AUTOSAR XML (schema 4-2-2)
package /ASW_NM
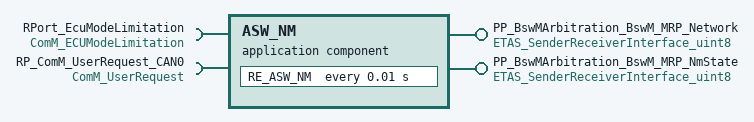
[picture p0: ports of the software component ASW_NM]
  application sw component type ASW_NM
    require port RPort_EcuModeLimitation: required-interface=ComM_ECUModeLimitation
    require port RP_ComM_UserRequest_CAN0: required-interface=ComM_UserRequest
    provide port PP_BswMArbitration_BswM_MRP_Network: provided-interface=ETAS_SenderReceiverInterface_uint8
    provide port PP_BswMArbitration_BswM_MRP_NmState: provided-interface=ETAS_SenderReceiverInterface_uint8
    behavior IB_ASW_NM: data-type-mapping=ComMModeMapping
      timing event TE_ASW_Nm_10ms: start-on-event=RE_ASW_NM, period=0.01
      runnable RE_ASW_NM: symbol=RE_ASW_NM_func
        data-send-points:
          access DSP_uint8_0: accessed-variable=PP_BswMArbitration_BswM_MRP_Network.uint8
          access DSP_uint8_1: accessed-variable=PP_BswMArbitration_BswM_MRP_NmState.uint8
        8 x sync call:
          SynchronousServerCallPoint_0: operation=RPort_EcuModeLimitation.LimitECUToNoComMode
          SynchronousServerCallPoint_1: operation=RPort_EcuModeLimitation.ReadInhibitCounter
          SynchronousServerCallPoint_2: operation=RPort_EcuModeLimitation.ResetInhibitCounter
          SynchronousServerCallPoint_3: operation=RPort_EcuModeLimitation.SetECUGroupClassification
          SynchronousServerCallPoint_4: operation=RP_ComM_UserRequest_CAN0.GetCurrentComMode
          SynchronousServerCallPoint_5: operation=RP_ComM_UserRequest_CAN0.GetMaxComMode
          SynchronousServerCallPoint_6: operation=RP_ComM_UserRequest_CAN0.GetRequestedComMode
          SynchronousServerCallPoint_7: operation=RP_ComM_UserRequest_CAN0.RequestComMode
